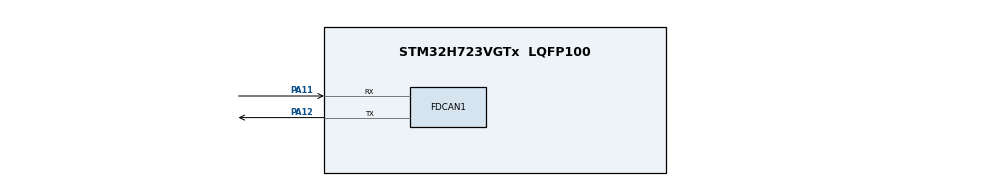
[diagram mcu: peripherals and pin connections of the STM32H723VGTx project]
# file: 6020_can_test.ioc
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FDCAN1.NominalPrescaler=3
FDCAN1.NominalSyncJumpWidth=2
FDCAN1.NominalTimeSeg1=13
FDCAN1.RxBuffersNbr=3
FDCAN1.RxFifo0ElmtsNbr=8
FDCAN1.StdFiltersNbr=4
FDCAN1.TxBuffersNbr=3
Mcu.Family=STM32H7
Mcu.Name=STM32H723VGTx
Mcu.Package=LQFP100
NVIC.FDCAN1_IT0_IRQn=true\:0\:0\:false\:false\:true\:true\:true
NVIC.PriorityGroup=NVIC_PRIORITYGROUP_4
PA11.Mode=FDCAN_Activate
PA11.Signal=FDCAN1_RX
PA12.Mode=FDCAN_Activate
PA12.Signal=FDCAN1_TX
PA13(JTMS/SWDIO).Mode=Serial_Wire
PA13(JTMS/SWDIO).Signal=DEBUG_JTMS-SWDIO
PA14(JTCK/SWCLK).Mode=Serial_Wire
PA14(JTCK/SWCLK).Signal=DEBUG_JTCK-SWCLK
PH0-OSC_IN.Mode=HSE-External-Oscillator
PH0-OSC_IN.Signal=RCC_OSC_IN
PH1-OSC_OUT.Mode=HSE-External-Oscillator
PH1-OSC_OUT.Signal=RCC_OSC_OUT
ProjectManager.HeapSize=0x200
ProjectManager.StackSize=0x400
ProjectManager.TargetToolchain=MDK-ARM V5.32
RCC.ADCFreq_Value=129000000
RCC.APB1Freq_Value=32000000
RCC.APB2Freq_Value=32000000
RCC.APB3Freq_Value=32000000
RCC.APB4Freq_Value=32000000
RCC.CortexFreq_Value=64000000
RCC.D1PPRE=RCC_APB3_DIV2
RCC.D2PPRE1=RCC_APB1_DIV2
RCC.D2PPRE2=RCC_APB2_DIV2
RCC.D3PPRE=RCC_APB4_DIV2
RCC.DIVM1=4
RCC.DIVN1=12
RCC.DIVQ1=4
RCC.HCLKFreq_Value=64000000
RCC.PLLFRACN=0
RCC.SYSCLKFreq_VALUE=64000000
RCC.USBFreq_Value=48000000
board=custom

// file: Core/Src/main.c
/* USER CODE BEGIN Header */
/**
  ******************************************************************************
  * @file           : main.c
  * @brief          : Main program body
  ******************************************************************************
  * @attention
  *
  * <h2><center>&copy; Copyright (c) 2026 STMicroelectronics.
  * All rights reserved.</center></h2>
  *
  * This software component is licensed by ST under BSD 3-Clause license,
  * the "License"; You may not use this file except in compliance with the
  * License. You may obtain a copy of the License at:
  *                        opensource.org/licenses/BSD-3-Clause
  *
  ******************************************************************************
  */
/* USER CODE END Header */
#include "main.h"
#include "fdcan.h"
#include "gpio.h"

/* USER CODE BEGIN PTD */

typedef struct
{int16_t angle;
int16_t current;
int16_t speed_rpm;
uint8_t teperate;}Motor6020;
/* USER CODE END PTD */

/* USER CODE BEGIN PV */
Motor6020 motor[8];
volatile uint8_t rx_flag=0;
/* USER CODE END PV */

void SystemClock_Config(void);
/* USER CODE BEGIN PFP */
void can_filter_init(void);
void decode_Motor6020(Motor6020 *m,uint8_t *data);
/* USER CODE END PFP */

int main(void)
{

  /* MCU Configuration--------------------------------------------------------*/

  /* Reset of all peripherals, Initializes the Flash interface and the Systick. */
  HAL_Init();

  /* Configure the system clock */
  SystemClock_Config();

  /* Initialize all configured peripherals */
  MX_GPIO_Init();
  MX_FDCAN1_Init();
  /* USER CODE BEGIN 2 */
HAL_FDCAN_ConfigGlobalFilter(&hfdcan1,FDCAN_ACCEPT_IN_RX_FIFO0,FDCAN_ACCEPT_IN_RX_FIFO0,
FDCAN_FILTER_REMOTE,FDCAN_FILTER_REMOTE);
can_filter_init();
HAL_FDCAN_Start(&hfdcan1);
  HAL_FDCAN_ActivateNotification(&hfdcan1, FDCAN_IT_RX_FIFO0_NEW_MESSAGE, 0);
  /* USER CODE END 2 */

  /* Infinite loop */
  while (1)
  {

  }
}

void SystemClock_Config(void)
{
  RCC_OscInitTypeDef RCC_OscInitStruct = {0};
  RCC_ClkInitTypeDef RCC_ClkInitStruct = {0};

  /** Supply configuration update enable
  */
  HAL_PWREx_ConfigSupply(PWR_LDO_SUPPLY);
  /** Configure the main internal regulator output voltage
  */
  __HAL_PWR_VOLTAGESCALING_CONFIG(PWR_REGULATOR_VOLTAGE_SCALE3);

  while(!__HAL_PWR_GET_FLAG(PWR_FLAG_VOSRDY)) {}
  /** Initializes the RCC Oscillators according to the specified parameters
  * in the RCC_OscInitTypeDef structure.
  */
  RCC_OscInitStruct.OscillatorType = RCC_OSCILLATORTYPE_HSI;
  RCC_OscInitStruct.HSIState = RCC_HSI_DIV1;
  RCC_OscInitStruct.HSICalibrationValue = RCC_HSICALIBRATION_DEFAULT;
  RCC_OscInitStruct.PLL.PLLState = RCC_PLL_ON;
  RCC_OscInitStruct.PLL.PLLSource = RCC_PLLSOURCE_HSI;
  RCC_OscInitStruct.PLL.PLLM = 4;
  RCC_OscInitStruct.PLL.PLLN = 12;
  RCC_OscInitStruct.PLL.PLLP = 2;
  RCC_OscInitStruct.PLL.PLLQ = 4;
  RCC_OscInitStruct.PLL.PLLR = 2;
  RCC_OscInitStruct.PLL.PLLRGE = RCC_PLL1VCIRANGE_3;
  RCC_OscInitStruct.PLL.PLLVCOSEL = RCC_PLL1VCOWIDE;
  RCC_OscInitStruct.PLL.PLLFRACN = 0;
  if (HAL_RCC_OscConfig(&RCC_OscInitStruct) != HAL_OK)
  {
    Error_Handler();
  }
  /** Initializes the CPU, AHB and APB buses clocks
  */
  RCC_ClkInitStruct.ClockType = RCC_CLOCKTYPE_HCLK|RCC_CLOCKTYPE_SYSCLK
                              |RCC_CLOCKTYPE_PCLK1|RCC_CLOCKTYPE_PCLK2
                              |RCC_CLOCKTYPE_D3PCLK1|RCC_CLOCKTYPE_D1PCLK1;
  RCC_ClkInitStruct.SYSCLKSource = RCC_SYSCLKSOURCE_HSI;
  RCC_ClkInitStruct.SYSCLKDivider = RCC_SYSCLK_DIV1;
  RCC_ClkInitStruct.AHBCLKDivider = RCC_HCLK_DIV1;
  RCC_ClkInitStruct.APB3CLKDivider = RCC_APB3_DIV2;
  RCC_ClkInitStruct.APB1CLKDivider = RCC_APB1_DIV2;
  RCC_ClkInitStruct.APB2CLKDivider = RCC_APB2_DIV2;
  RCC_ClkInitStruct.APB4CLKDivider = RCC_APB4_DIV2;

  if (HAL_RCC_ClockConfig(&RCC_ClkInitStruct, FLASH_LATENCY_1) != HAL_OK)
  {
    Error_Handler();
  }
}

/* USER CODE BEGIN 4 */
void can_filter_init(void)
{
  FDCAN_FilterTypeDef fdcan_filter_st;
  fdcan_filter_st.IdType=FDCAN_STANDARD_ID;
  fdcan_filter_st.FilterIndex=0;
  fdcan_filter_st.FilterType=FDCAN_FILTER_MASK;
  fdcan_filter_st.FilterConfig=FDCAN_FILTER_TO_RXFIFO0;
    fdcan_filter_st.FilterID1    = 0x000;
  fdcan_filter_st.FilterID2    = 0x000;
HAL_FDCAN_ConfigFilter(&hfdcan1,&fdcan_filter_st);
}
void decode_Motor6020(Motor6020 *motor,uint8_t *data)
{motor->angle=(data[0]<<8)|data[1];
motor->speed_rpm=(data[2]<<8)|data[3];
motor->current=(data[4]<<8)|data[5];
motor->teperate=data[6];}
void HAL_FDCAN_RxFifo0Callback(FDCAN_HandleTypeDef *hcan,uint32_t it)
{FDCAN_RxHeaderTypeDef rx_header;
  uint8_t rx_data[8];uint8_t id;
  if(HAL_FDCAN_GetRxMessage(hcan,FDCAN_RX_FIFO0,&rx_header,rx_data)!=HAL_OK)
  {return;}
if(rx_header.Identifier<0x205||rx_header.Identifier>0x20B)
{return;}
id=(uint8_t)(rx_header.Identifier-0x204);
decode_Motor6020(&motor[id],rx_data);
rx_flag=1;
}
/* USER CODE END 4 */

void Error_Handler(void)
{
  __disable_irq();
  while (1)
  {
  }
}

/************************ (C) COPYRIGHT STMicroelectronics *****END OF FILE****/
